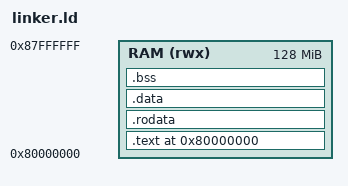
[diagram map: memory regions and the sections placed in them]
OUTPUT_ARCH(riscv)
ENTRY(_start)

MEMORY {
  RAM (rwx) : ORIGIN = 0x80000000, LENGTH = 128M
}

SECTIONS {
  . = ORIGIN(RAM);

  .text : {
    KEEP(*(.text.start))
    *(.text*)
  } > RAM

  .rodata : {
    *(.rodata*)
  } > RAM

  .data : {
    *(.data*)
  } > RAM

  .bss (NOLOAD) : {
    __bss_start = .;
    *(.bss*)
    *(COMMON)
    __bss_end = .;
  } > RAM

  . = ALIGN(16);
  __stack_bottom = .;
  . = . + 16K;
  __stack_top = .;
}
